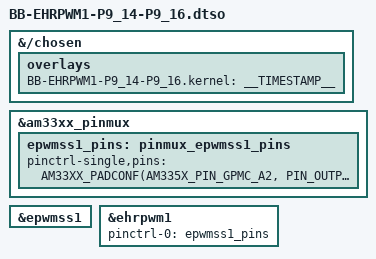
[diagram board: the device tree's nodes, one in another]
// SPDX-License-Identifier: GPL-2.0-only
/*
 * Copyright (C) 2025 Robert Nelson <robertcnelson@gmail.com>
 */

/dts-v1/;
/plugin/;

#include <dt-bindings/pinctrl/am33xx.h>

/*
 * Helper to show loaded overlays under: /proc/device-tree/chosen/overlays/
 */
&{/chosen} {
	overlays {
		BB-EHRPWM1-P9_14-P9_16.kernel = __TIMESTAMP__;
	};
};

&am33xx_pinmux {
	epwmss1_pins: pinmux_epwmss1_pins {
		pinctrl-single,pins = <
			AM33XX_PADCONF(AM335X_PIN_GPMC_A2, PIN_OUTPUT, MUX_MODE6) /* P9_14 (U14) gpmc_a2.ehrpwm1A */
			AM33XX_PADCONF(AM335X_PIN_GPMC_A3, PIN_OUTPUT, MUX_MODE6) /* P9_16 (T14) gpmc_a3.ehrpwm1B */
		>;
	};
};

&epwmss1 {
	status = "okay";
};

&ehrpwm1 {
	status = "okay";
	pinctrl-names = "default";
	pinctrl-0 = <&epwmss1_pins>;
};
